VERSION ""

NS_ :

BS_:
BU_: SENSOR_MODULE E_BOX PI VESC Throttle
BO_ 2147485696 PORT_SONAR: 8 SENSOR_MODULE
   SG_ PORT_SONAR_HEIGHT : 1|16@0+ (1,0) [0|6000] "mm" PI

BO_ 2147485697 STARBOARD_SONAR: 8 SENSOR_MODULE
   SG_ STARBOARD_SONAR_HEIGHT : 1|16@0+ (1,0) [0|6000] "mm" PI

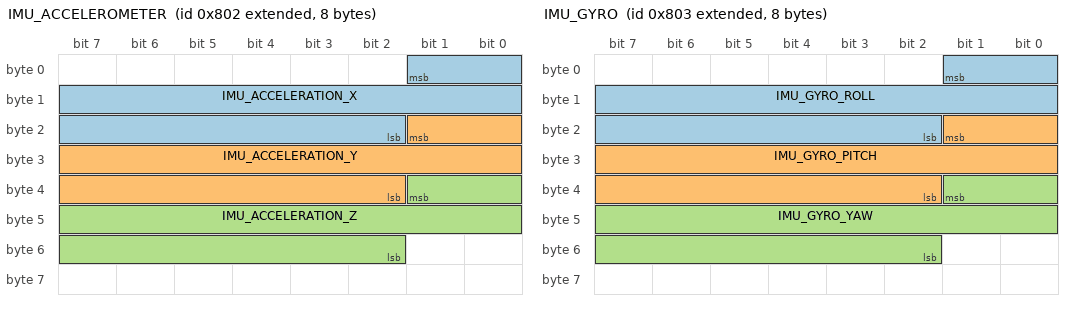
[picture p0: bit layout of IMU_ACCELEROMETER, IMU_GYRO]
BO_ 2147485698 IMU_ACCELEROMETER: 8 SENSOR_MODULE
   SG_ IMU_ACCELERATION_X : 1|16@0- (0.001,0) [-50|50] "" PI
   SG_ IMU_ACCELERATION_Y : 17|16@0- (0.001,0) [-50|50] "" PI
   SG_ IMU_ACCELERATION_Z : 33|16@0- (0.001,0) [-50|50] "" PI

BO_ 2147485699 IMU_GYRO: 8 SENSOR_MODULE
   SG_ IMU_GYRO_ROLL : 1|16@0- (0.001,0) [-250|250] "" PI
   SG_ IMU_GYRO_PITCH : 17|16@0- (0.001,0) [-250|250] "" PI
   SG_ IMU_GYRO_YAW : 33|16@0- (0.001,0) [-250|250] "" PI

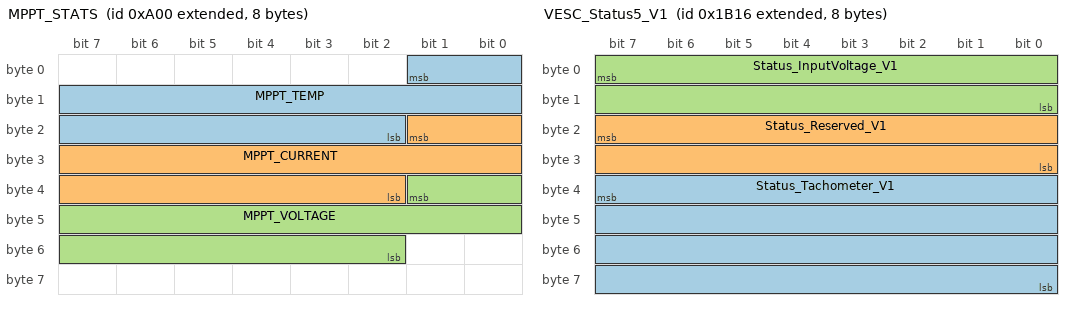
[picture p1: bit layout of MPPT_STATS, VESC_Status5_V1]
BO_ 2147486208 MPPT_STATS: 8 E_BOX
   SG_ MPPT_TEMP : 1|16@0- (0.01,0) [-100|100] "C" PI
   SG_ MPPT_CURRENT : 17|16@0+ (0.1,0) [0|1] "A" PI
   SG_ MPPT_VOLTAGE : 33|16@0+ (0.1,0) [0|1] "V" PI

BO_ 2147486210 PMU: 8 E_BOX
   SG_ PMU_TEMP : 1|16@0- (0.01,0) [-100|100] "C" PI

BO_ 2147486209 AFT_SONAR: 8 E_BOX
   SG_ AFT_SONAR_HEIGHT : 1|16@0+ (1,0) [0|6000] "mm" PI

BO_ 2147485700 IMU_TEMP: 8 SENSOR_MODULE
   SG_ IMU_TEMPERATURE : 1|16@0+ (0.01,0) [-30|100] "C" PI

BO_ 22 SETDUTY: 4 Throttle
   SG_ SET_DUTY_signed : 7|32@0- (0.001,0) [-100|100] "" Throttle

BO_ 2147490582 VESC_Status5_V1: 8 VESC
   SG_ Status_Tachometer_V1 : 39|32@0- (1,0) [0|0] "RPM" PI
   SG_ Status_Reserved_V1 : 23|16@0- (1,0) [0|0] "" PI
   SG_ Status_InputVoltage_V1 : 7|16@0- (0.1,0) [0|0] "" PI

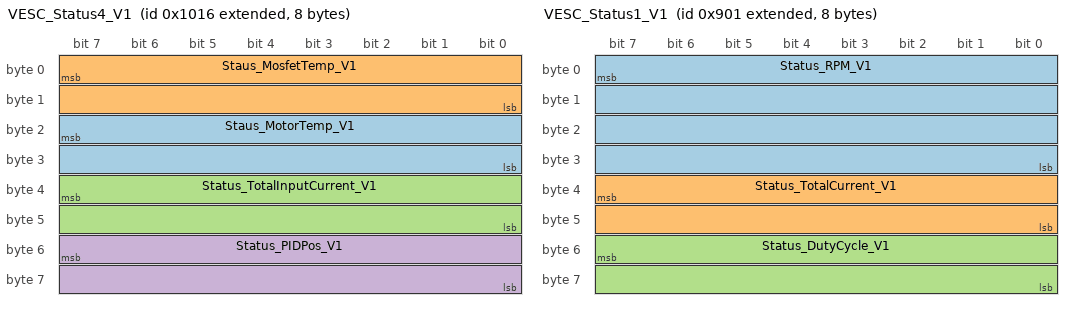
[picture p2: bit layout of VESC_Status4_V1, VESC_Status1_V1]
BO_ 2147487766 VESC_Status4_V1: 8 VESC
   SG_ Staus_MotorTemp_V1 : 23|16@0- (0.1,0) [-3276.8|3276.7] "C" PI
   SG_ Staus_MosfetTemp_V1 : 7|16@0- (0.1,0) [-3276.8|3276.7] "C" PI
   SG_ Status_TotalInputCurrent_V1 : 39|16@0- (0.1,0) [-3276.8|3276.7] "A" PI
   SG_ Status_PIDPos_V1 : 55|16@0- (0.02,0) [-655.36|655.34] "" PI

BO_ 2147487510 VESC_Status3_V1: 8 VESC
   SG_ Status_WattHoursCharged_V1 : 39|32@0- (1e-05,0) [-21474.8|21474.8] "Wh" PI
   SG_ Status_WattHours_V1 : 7|32@0- (1e-05,0) [-21474.8|21474.8] "Wh" PI

BO_ 2147487254 VESC_Status2_V1: 8 VESC
   SG_ Status_AmpHoursCharged_V1 : 39|32@0- (1e-05,0) [-21474.8|21474.8] "Ah" PI
   SG_ Status_AmpHours_V1 : 7|32@0- (1e-05,0) [-21474.8|21474.8] "Ah" PI

BO_ 2147485953 VESC_Status1_V1: 8 VESC
   SG_ Status_RPM_V1 : 7|32@0- (1,0) [-2.14748e+09|2.14748e+09] "RPM" PI
   SG_ Status_TotalCurrent_V1 : 39|16@0- (0.1,0) [-3276.8|3276.7] "A" PI
   SG_ Status_DutyCycle_V1 : 55|16@0- (0.1,0) [-100|100] "%" PI

BO_ 2147483649 VESC_Command_DutyCycle_V1: 4 PI
   SG_ Command_DutyCycle_V1 : 7|32@0- (0.001,0) [-100|100] "%" VESC

CM_ BO_ 2147485953 "vesc some how uses id 1 here";
BA_DEF_ BO_ "GenMsgBackgroundColor" STRING ;
BA_DEF_ BO_ "GenMsgForegroundColor" STRING ;
BA_DEF_ BO_ "filterlabeling" INT 0 0;
BA_DEF_ BO_ "filterlabeling" INT 0 0;
BA_DEF_DEF_ "GenMsgBackgroundColor" "#ffffff";
BA_DEF_DEF_ "GenMsgForegroundColor" "#000000";
BA_DEF_DEF_ "filterlabeling" 1;
